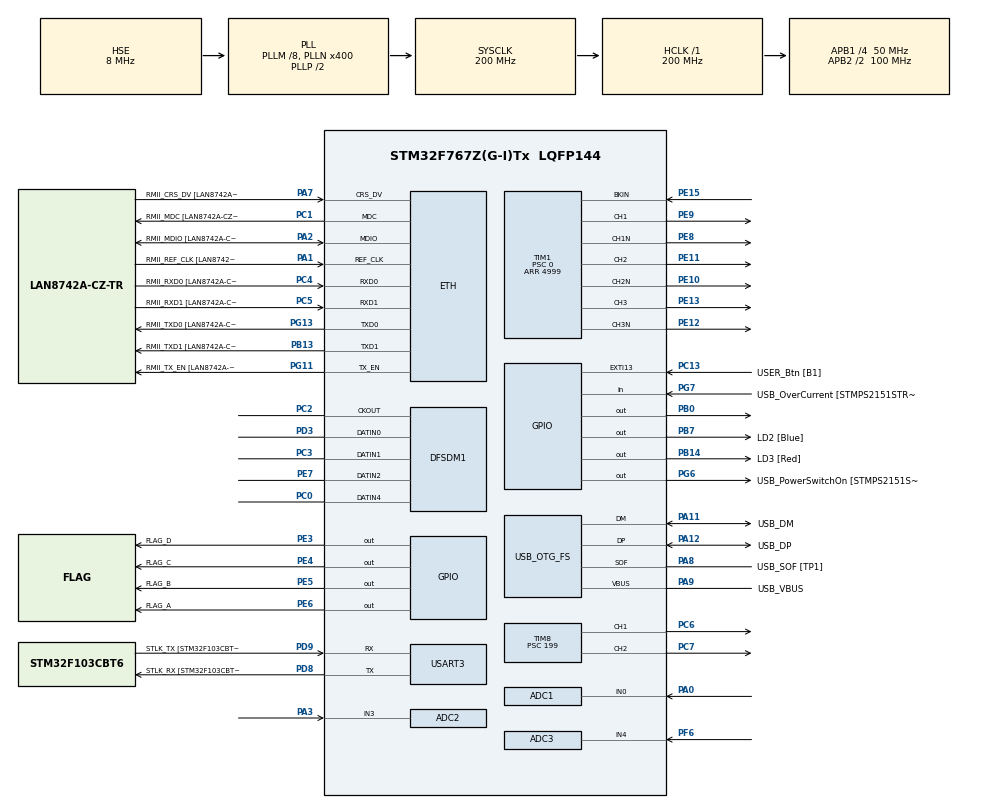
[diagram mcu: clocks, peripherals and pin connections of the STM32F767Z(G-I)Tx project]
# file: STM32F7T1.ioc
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ADC1.Channel-4\#ChannelRegularConversion=ADC_CHANNEL_0
ADC1.ClockPrescaler=ADC_CLOCK_SYNC_PCLK_DIV4
ADC1.NbrOfConversionFlag=1
ADC1.Rank-4\#ChannelRegularConversion=1
ADC1.SamplingTime-4\#ChannelRegularConversion=ADC_SAMPLETIME_3CYCLES
ADC1.master=1
ADC2.Channel-4\#ChannelRegularConversion=ADC_CHANNEL_3
ADC2.ClockPrescaler=ADC_CLOCK_SYNC_PCLK_DIV4
ADC2.NbrOfConversionFlag=1
ADC2.Rank-4\#ChannelRegularConversion=1
ADC2.SamplingTime-4\#ChannelRegularConversion=ADC_SAMPLETIME_3CYCLES
ADC3.Channel-0\#ChannelRegularConversion=ADC_CHANNEL_4
ADC3.ClockPrescaler=ADC_CLOCK_SYNC_PCLK_DIV4
ADC3.NbrOfConversionFlag=1
ADC3.Rank-0\#ChannelRegularConversion=1
ADC3.SamplingTime-0\#ChannelRegularConversion=ADC_SAMPLETIME_3CYCLES
CORTEX_M7.ART_ACCLERATOR_ENABLE=1
CORTEX_M7.CPU_DCache=Enabled
CORTEX_M7.CPU_ICache=Enabled
CORTEX_M7.PREFETCH_ENABLE=1
DFSDM1.Divider=256
DFSDM1.FastMode_reg_FIL0=ENABLE
DFSDM1.FastMode_reg_FIL1=ENABLE
DFSDM1.FastMode_reg_FIL2=ENABLE
DFSDM1.FastMode_reg_FIL3=ENABLE
DFSDM1.FilterOrder_CH0=DFSDM_CHANNEL_SINC3_ORDER
DFSDM1.FilterOrder_CH1=DFSDM_CHANNEL_SINC3_ORDER
DFSDM1.FilterOrder_CH2=DFSDM_CHANNEL_SINC3_ORDER
DFSDM1.FilterOrder_CH4=DFSDM_CHANNEL_SINC3_ORDER
DFSDM1.Filter_regChannel_FIL0=DFSDM_CHANNEL_0
DFSDM1.Filter_regChannel_FIL1=DFSDM_CHANNEL_1
DFSDM1.Filter_regChannel_FIL2=DFSDM_CHANNEL_2
DFSDM1.Filter_regChannel_FIL3=DFSDM_CHANNEL_4
DFSDM1.Fosr_FIL0=32
DFSDM1.Fosr_FIL1=32
DFSDM1.Fosr_FIL2=32
DFSDM1.Fosr_FIL3=32
DFSDM1.Oversampling_CH0=32
DFSDM1.Oversampling_CH1=32
DFSDM1.Oversampling_CH2=32
DFSDM1.Oversampling_CH4=32
DFSDM1.SincOrder_FIL0=DFSDM_FILTER_SINC3_ORDER
DFSDM1.SincOrder_FIL1=DFSDM_FILTER_SINC3_ORDER
DFSDM1.SincOrder_FIL2=DFSDM_FILTER_SINC3_ORDER
DFSDM1.SincOrder_FIL3=DFSDM_FILTER_SINC3_ORDER
ETH.MediaInterface=ETH_MEDIA_INTERFACE_RMII
FREERTOS.Tasks01=defaultTask,-3,128,StartDefaultTask,Default,NULL,Dynamic,NULL,NULL;TNBlinky,0,128,ThreadBlinky,As external,NULL,Dynamic,NULL,NULL;TNDFSDM,0,128,ThreadDFSDM,As external,NULL,Dynamic,NULL,NULL;TNCDC,0,128,ThreadCDC,As external,NULL,Dynamic,NULL,NULL;TNPWM,0,128,ThreadPWM,As external,NULL,Dynamic,NULL,NULL
FREERTOS.configLIBRARY_MAX_SYSCALL_INTERRUPT_PRIORITY=6
Mcu.Family=STM32F7
Mcu.Name=STM32F767Z(G-I)Tx
Mcu.Package=LQFP144
NVIC.OTG_FS_IRQn=true\:6\:0\:false\:false\:true\:true
NVIC.PriorityGroup=NVIC_PRIORITYGROUP_4
NVIC.TIM1_CC_IRQn=true\:6\:0\:false\:false\:true\:true
NVIC.TIM1_UP_TIM10_IRQn=true\:6\:0\:false\:false\:true\:true
NVIC.TIM3_IRQn=true\:6\:0\:false\:false\:true\:true
NVIC.TIM6_DAC_IRQn=true\:0\:0\:false\:false\:true\:false
NVIC.TimeBase=TIM6_DAC_IRQn
NVIC.TimeBaseIP=TIM6
PA0/WKUP.Signal=ADCx_IN0
PA1.GPIO_Label=RMII_REF_CLK [LAN8742A-CZ-TR_REFCLK0]
PA1.Mode=RMII
PA1.Signal=ETH_REF_CLK
PA10.Signal=USB_OTG_FS_ID
PA11.GPIO_Label=USB_DM
PA11.Mode=Device_Only
PA11.Signal=USB_OTG_FS_DM
PA12.GPIO_Label=USB_DP
PA12.Mode=Device_Only
PA12.Signal=USB_OTG_FS_DP
PA13.GPIO_Label=TMS
PA13.Mode=Trace_Asynchronous_SW
PA13.Signal=SYS_JTMS-SWDIO
PA14.GPIO_Label=TCK
PA14.Mode=Trace_Asynchronous_SW
PA14.Signal=SYS_JTCK-SWCLK
PA2.GPIO_Label=RMII_MDIO [LAN8742A-CZ-TR_MDIO]
PA2.Mode=RMII
PA2.Signal=ETH_MDIO
PA3.Signal=ADCx_IN3
PA7.GPIO_Label=RMII_CRS_DV [LAN8742A-CZ-TR_CRS_DV]
PA7.Mode=RMII
PA7.Signal=ETH_CRS_DV
PA8.GPIO_Label=USB_SOF [TP1]
PA8.Mode=Activate_SOF_FS
PA8.Signal=USB_OTG_FS_SOF
PA9.GPIO_Label=USB_VBUS
PA9.Mode=Activate_VBUS
PA9.Signal=USB_OTG_FS_VBUS
PB0.Signal=GPIO_Output
PB13.GPIO_Label=RMII_TXD1 [LAN8742A-CZ-TR_TXD1]
PB13.Mode=RMII
PB13.Signal=ETH_TXD1
PB14.GPIO_Label=LD3 [Red]
PB14.Signal=GPIO_Output
PB3.GPIO_Label=SW0
PB3.Mode=Trace_Asynchronous_SW
PB3.Signal=SYS_JTDO-SWO
PB7.GPIO_Label=LD2 [Blue]
PB7.Signal=GPIO_Output
PC0.Signal=S_DATAIN4DFSDM1
PC1.GPIO_Label=RMII_MDC [LAN8742A-CZ-TR_MDC]
PC1.Mode=RMII
PC1.Signal=ETH_MDC
PC13.GPIO_Label=USER_Btn [B1]
PC13.Signal=GPXTI13
PC14/OSC32_IN.Mode=LSE-External-Oscillator
PC14/OSC32_IN.Signal=RCC_OSC32_IN
PC15/OSC32_OUT.Mode=LSE-External-Oscillator
PC15/OSC32_OUT.Signal=RCC_OSC32_OUT
PC2.Signal=S_CKOUTDFSDM1
PC3.Signal=S_DATAIN1DFSDM1
PC4.GPIO_Label=RMII_RXD0 [LAN8742A-CZ-TR_RXD0]
PC4.Mode=RMII
PC4.Signal=ETH_RXD0
PC5.GPIO_Label=RMII_RXD1 [LAN8742A-CZ-TR_RXD1]
PC5.Mode=RMII
PC5.Signal=ETH_RXD1
PC6.Signal=S_TIM8_CH1
PC7.Signal=S_TIM8_CH2
PD3.Signal=S_DATAIN0DFSDM1
PD8.GPIO_Label=STLK_RX [STM32F103CBT6_PA3]
PD8.Mode=Asynchronous
PD8.Signal=USART3_TX
PD9.GPIO_Label=STLK_TX [STM32F103CBT6_PA2]
PD9.Mode=Asynchronous
PD9.Signal=USART3_RX
PE10.Mode=PWM Generation2 CH2 CH2N
PE10.Signal=TIM1_CH2N
PE11.Signal=S_TIM1_CH2
PE12.Mode=PWM Generation3 CH3 CH3N
PE12.Signal=TIM1_CH3N
PE13.Signal=S_TIM1_CH3
PE15.Mode=Activate-Break-Input
PE15.Signal=TIM1_BKIN
PE3.GPIO_Label=FLAG_D
PE3.GPIO_ModeDefaultOutputPP=GPIO_MODE_OUTPUT_OD
PE3.GPIO_PuPd=GPIO_PULLUP
PE3.GPIO_Speed=GPIO_SPEED_FREQ_MEDIUM
PE3.Signal=GPIO_Output
PE4.GPIO_Label=FLAG_C
PE4.GPIO_ModeDefaultOutputPP=GPIO_MODE_OUTPUT_OD
PE4.GPIO_PuPd=GPIO_PULLUP
PE4.GPIO_Speed=GPIO_SPEED_FREQ_MEDIUM
PE4.Signal=GPIO_Output
PE5.GPIO_Label=FLAG_B
PE5.GPIO_ModeDefaultOutputPP=GPIO_MODE_OUTPUT_OD
PE5.GPIO_PuPd=GPIO_PULLUP
PE5.GPIO_Speed=GPIO_SPEED_FREQ_MEDIUM
PE5.PinState=GPIO_PIN_RESET
PE5.Signal=GPIO_Output
PE6.GPIO_Label=FLAG_A
PE6.GPIO_ModeDefaultOutputPP=GPIO_MODE_OUTPUT_OD
PE6.GPIO_PuPd=GPIO_PULLUP
PE6.GPIO_Speed=GPIO_SPEED_FREQ_MEDIUM
PE6.Signal=GPIO_Output
PE7.Signal=S_DATAIN2DFSDM1
PE8.Mode=PWM Generation1 CH1 CH1N
PE8.Signal=TIM1_CH1N
PE9.Signal=S_TIM1_CH1
PF6.Mode=IN4
PF6.Signal=ADC3_IN4
PG11.GPIO_Label=RMII_TX_EN [LAN8742A-CZ-TR_TXEN]
PG11.Mode=RMII
PG11.Signal=ETH_TX_EN
PG13.GPIO_Label=RMII_TXD0 [LAN8742A-CZ-TR_TXD0]
PG13.Mode=RMII
PG13.Signal=ETH_TXD0
PG6.GPIO_Label=USB_PowerSwitchOn [STMPS2151STR_EN]
PG6.Signal=GPIO_Output
PG7.GPIO_Label=USB_OverCurrent [STMPS2151STR_FAULT]
PG7.Signal=GPIO_Input
PH0/OSC_IN.GPIO_Label=MCO [STM32F103CBT6_PA8]
PH0/OSC_IN.Mode=HSE-External-Clock-Source
PH0/OSC_IN.Signal=RCC_OSC_IN
PH1/OSC_OUT.Mode=HSE-External-Clock-Source
PH1/OSC_OUT.Signal=RCC_OSC_OUT
ProjectManager.HeapSize=0x200
ProjectManager.StackSize=0x400
ProjectManager.TargetToolchain=SW4STM32
RCC.48MHZClocksFreq_Value=24000000
RCC.AHBFreq_Value=200000000
RCC.APB1CLKDivider=RCC_HCLK_DIV4
RCC.APB1Freq_Value=50000000
RCC.APB1TimFreq_Value=100000000
RCC.APB2CLKDivider=RCC_HCLK_DIV2
RCC.APB2Freq_Value=100000000
RCC.APB2TimFreq_Value=200000000
RCC.CortexFreq_Value=200000000
RCC.DFSDMSelection=RCC_DFSDM1CLKSOURCE_SYSCLK
RCC.HCLKFreq_Value=200000000
RCC.HSE_VALUE=8000000
RCC.HSI_VALUE=16000000
RCC.PLL48CLockSelection=RCC_CLK48SOURCE_PLLSAIP
RCC.PLLM=8
RCC.PLLMUL=RCC_PLL_MUL9
RCC.PLLN=400
RCC.PLLSAIP=RCC_PLLSAIP_DIV4
RCC.PRESCALERUSB=RCC_USBCLKSOURCE_PLL_DIV1_5
RCC.SYSCLKFreq_VALUE=200000000
RCC.SYSCLKSource=RCC_SYSCLKSOURCE_PLLCLK
RCC.SYSCLKSourceVirtual=RCC_SYSCLKSOURCE_PLLCLK
RCC.USART3CLockSelection=RCC_USART3CLKSOURCE_SYSCLK
RCC.USBFreq_Value=48000000
RCC.VCOOutputFreq_Value=400000000
SH.ADCx_IN0.0=ADC1_IN0,IN0
SH.ADCx_IN3.0=ADC2_IN3,IN3
SH.S_CKOUTDFSDM1.0=DFSDM1_CKOUT,PDM_SPI_input_from_ch0_and_internal_clock
SH.S_CKOUTDFSDM1.1=DFSDM1_CKOUT,PDM_SPI_input_from_ch1_and_internal_clock
SH.S_CKOUTDFSDM1.2=DFSDM1_CKOUT,PDM_SPI_input_from_ch2_and_internal_clock
SH.S_CKOUTDFSDM1.3=DFSDM1_CKOUT,CKOUT
SH.S_CKOUTDFSDM1.4=DFSDM1_CKOUT,PDM_SPI_input_from_ch4_and_internal_clock
SH.S_DATAIN0DFSDM1.0=DFSDM1_DATIN0,PDM_SPI_input_from_ch0_and_internal_clock
SH.S_DATAIN1DFSDM1.0=DFSDM1_DATIN1,PDM_SPI_input_from_ch1_and_internal_clock
SH.S_DATAIN2DFSDM1.0=DFSDM1_DATIN2,PDM_SPI_input_from_ch2_and_internal_clock
SH.S_DATAIN4DFSDM1.0=DFSDM1_DATIN4,PDM_SPI_input_from_ch4_and_internal_clock
SH.S_TIM1_CH1.0=TIM1_CH1,PWM Generation1 CH1 CH1N
SH.S_TIM1_CH2.0=TIM1_CH2,PWM Generation2 CH2 CH2N
SH.S_TIM1_CH3.0=TIM1_CH3,PWM Generation3 CH3 CH3N
SH.S_TIM8_CH1.0=TIM8_CH1,Output Compare1 CH1
SH.S_TIM8_CH2.0=TIM8_CH2,Output Compare2 CH2
TIM1.AutomaticOutput=TIM_AUTOMATICOUTPUT_ENABLE
TIM1.BreakState=TIM_BREAK_DISABLE
TIM1.Channel-Output\ Compare4\ No\ Output=TIM_CHANNEL_4
TIM1.Channel-PWM\ Generation1\ CH1\ CH1N=TIM_CHANNEL_1
TIM1.Channel-PWM\ Generation2\ CH2\ CH2N=TIM_CHANNEL_2
TIM1.Channel-PWM\ Generation3\ CH3\ CH3N=TIM_CHANNEL_3
TIM1.ClockDivision=TIM_CLOCKDIVISION_DIV4
TIM1.CounterMode=TIM_COUNTERMODE_CENTERALIGNED1
TIM1.DeadTime=50
TIM1.OCMode_PWM-PWM\ Generation1\ CH1\ CH1N=TIM_OCMODE_PWM1
TIM1.OCMode_PWM-PWM\ Generation2\ CH2\ CH2N=TIM_OCMODE_PWM1
TIM1.OCMode_PWM-PWM\ Generation3\ CH3\ CH3N=TIM_OCMODE_PWM1
TIM1.Period=4999
TIM1.Prescaler=0
TIM1.Pulse-Output\ Compare4\ No\ Output=400
TIM1.Pulse-PWM\ Generation1\ CH1\ CH1N=30
TIM1.Pulse-PWM\ Generation2\ CH2\ CH2N=13
TIM1.Pulse-PWM\ Generation3\ CH3\ CH3N=18
TIM1.RepetitionCounter=0
TIM1.SourceBRKDigInput=TIM_BREAKINPUTSOURCE_DISABLE
TIM1.TIM_MasterOutputTrigger=TIM_TRGO_UPDATE
TIM1.TIM_MasterOutputTrigger2=TIM_TRGO2_OC6REF
TIM1.TIM_MasterSlaveMode=TIM_MASTERSLAVEMODE_ENABLE
TIM3.Period=3
TIM3.TIM_MasterOutputTrigger=TIM_TRGO_UPDATE
TIM3.TIM_MasterSlaveMode=TIM_MASTERSLAVEMODE_DISABLE
TIM7.Period=999
TIM7.Prescaler=19
TIM8.Channel-Output\ Compare1\ CH1=TIM_CHANNEL_1
TIM8.Channel-Output\ Compare2\ CH2=TIM_CHANNEL_2
TIM8.Period=1000
TIM8.Prescaler=199
USART3.VirtualMode-Asynchronous=VM_ASYNC
USB_DEVICE.CLASS_NAME_FS=CDC
USB_DEVICE.SERIALNUMBER_STRING_CDC_FS=22345112
USB_DEVICE.VirtualModeFS=Cdc_FS
USB_OTG_FS.VirtualMode=Device_Only
VP_FREERTOS_VS_ENABLE.Mode=Enabled
VP_SYS_VS_tim6.Mode=TIM6
VP_TIM1_VS_ClockSourceINT.Mode=Internal
VP_TIM1_VS_no_output4.Mode=Output Compare4 No Output
VP_TIM3_VS_ClockSourceITR.Mode=TriggerSource_ITR0
VP_TIM3_VS_ControllerModeClock.Mode=Clock Mode
VP_TIM7_VS_ClockSourceINT.Mode=Enable_Timer
VP_TIM8_VS_ClockSourceINT.Mode=Internal
VP_USB_DEVICE_VS_USB_DEVICE_CDC_FS.Mode=CDC_FS
board=NUCLEO-F767ZI

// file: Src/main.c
/**
  ******************************************************************************
  * File Name          : main.c
  * Description        : Main program body
  ******************************************************************************
  * This notice applies to any and all portions of this file
  * that are not between comment pairs USER CODE BEGIN and
  * USER CODE END. Other portions of this file, whether
  * inserted by the user or by software development tools
  * are owned by their respective copyright owners.
  *
  * Copyright (c) 2017 STMicroelectronics International N.V.
  * All rights reserved.
  *
  * Redistribution and use in source and binary forms, with or without
  * modification, are permitted, provided that the following conditions are met:
  *
  * 1. Redistribution of source code must retain the above copyright notice,
  *    this list of conditions and the following disclaimer.
  * 2. Redistributions in binary form must reproduce the above copyright notice,
  *    this list of conditions and the following disclaimer in the documentation
  *    and/or other materials provided with the distribution.
  * 3. Neither the name of STMicroelectronics nor the names of other
  *    contributors to this software may be used to endorse or promote products
  *    derived from this software without specific written permission.
  * 4. This software, including modifications and/or derivative works of this
  *    software, must execute solely and exclusively on microcontroller or
  *    microprocessor devices manufactured by or for STMicroelectronics.
  * 5. Redistribution and use of this software other than as permitted under
  *    this license is void and will automatically terminate your rights under
  *    this license.
  *
  * THIS SOFTWARE IS PROVIDED BY STMICROELECTRONICS AND CONTRIBUTORS "AS IS"
  * AND ANY EXPRESS, IMPLIED OR STATUTORY WARRANTIES, INCLUDING, BUT NOT
  * LIMITED TO, THE IMPLIED WARRANTIES OF MERCHANTABILITY, FITNESS FOR A
  * PARTICULAR PURPOSE AND NON-INFRINGEMENT OF THIRD PARTY INTELLECTUAL PROPERTY
  * RIGHTS ARE DISCLAIMED TO THE FULLEST EXTENT PERMITTED BY LAW. IN NO EVENT
  * SHALL STMICROELECTRONICS OR CONTRIBUTORS BE LIABLE FOR ANY DIRECT, INDIRECT,
  * INCIDENTAL, SPECIAL, EXEMPLARY, OR CONSEQUENTIAL DAMAGES (INCLUDING, BUT NOT
  * LIMITED TO, PROCUREMENT OF SUBSTITUTE GOODS OR SERVICES; LOSS OF USE, DATA,
  * OR PROFITS; OR BUSINESS INTERRUPTION) HOWEVER CAUSED AND ON ANY THEORY OF
  * LIABILITY, WHETHER IN CONTRACT, STRICT LIABILITY, OR TORT (INCLUDING
  * NEGLIGENCE OR OTHERWISE) ARISING IN ANY WAY OUT OF THE USE OF THIS SOFTWARE,
  * EVEN IF ADVISED OF THE POSSIBILITY OF SUCH DAMAGE.
  *
  ******************************************************************************
  */
#include "main.h"
#include "stm32f7xx_hal.h"
#include "cmsis_os.h"
#include "adc.h"
#include "dfsdm.h"
#include "eth.h"
#include "tim.h"
#include "usart.h"
#include "usb_device.h"
#include "gpio.h"

/* USER CODE BEGIN Includes */
#include "intersect/event.h"
/* USER CODE END Includes */

/* USER CODE BEGIN PV */
/* Private variables ---------------------------------------------------------*/

/* USER CODE END PV */

void SystemClock_Config(void);
void MX_FREERTOS_Init(void);

/* USER CODE BEGIN PFP */
/* Private function prototypes -----------------------------------------------*/

/* USER CODE END PFP */

extern uint32_t g_pfnVectors;
extern uint32_t _vector_table_start;
//extern uint32_t isr_vector;

uint32_t readback;

int main(void)
{

  /* USER CODE BEGIN 1 */
	//SCB->VTOR = isr_vector;
	SCB->VTOR = _vector_table_start;
	SCB->VTOR = 0X08010000;
	readback = SCB->VTOR;
	/* USER CODE END 1 */

  /* Enable I-Cache-------------------------------------------------------------*/
  SCB_EnableICache();

  /* Enable D-Cache-------------------------------------------------------------*/
  SCB_EnableDCache();

  /* MCU Configuration----------------------------------------------------------*/

  /* Reset of all peripherals, Initializes the Flash interface and the Systick. */
  HAL_Init();

  /* Configure the system clock */
  SystemClock_Config();

  /* Initialize all configured peripherals */
  MX_GPIO_Init();
  MX_DFSDM1_Init();
  MX_TIM1_Init();
  MX_ADC1_Init();
  MX_ADC2_Init();
  MX_ADC3_Init();
  MX_TIM3_Init();
  MX_ETH_Init();
  MX_USART3_UART_Init();
  MX_TIM8_Init();
  MX_TIM7_Init();

  /* Call init function for freertos objects (in freertos.c) */
  MX_FREERTOS_Init();

  /* Start scheduler */
  osKernelStart();

  /* We should never get here as control is now taken by the scheduler */

  /* Infinite loop */
  while (1)
  {

  }

}

/** System Clock Configuration
*/
void SystemClock_Config(void)
{

  RCC_OscInitTypeDef RCC_OscInitStruct;
  RCC_ClkInitTypeDef RCC_ClkInitStruct;
  RCC_PeriphCLKInitTypeDef PeriphClkInitStruct;

    /**Configure the main internal regulator output voltage
    */
  __HAL_RCC_PWR_CLK_ENABLE();

  __HAL_PWR_VOLTAGESCALING_CONFIG(PWR_REGULATOR_VOLTAGE_SCALE1);

    /**Initializes the CPU, AHB and APB busses clocks
    */
  RCC_OscInitStruct.OscillatorType = RCC_OSCILLATORTYPE_HSE;
  RCC_OscInitStruct.HSEState = RCC_HSE_BYPASS;
  RCC_OscInitStruct.PLL.PLLState = RCC_PLL_ON;
  RCC_OscInitStruct.PLL.PLLSource = RCC_PLLSOURCE_HSE;
  RCC_OscInitStruct.PLL.PLLM = 8;
  RCC_OscInitStruct.PLL.PLLN = 400;
  RCC_OscInitStruct.PLL.PLLP = RCC_PLLP_DIV2;
  RCC_OscInitStruct.PLL.PLLQ = 2;
  if (HAL_RCC_OscConfig(&RCC_OscInitStruct) != HAL_OK)
  {
    _Error_Handler(__FILE__, __LINE__);
  }

    /**Activate the Over-Drive mode
    */
  if (HAL_PWREx_EnableOverDrive() != HAL_OK)
  {
    _Error_Handler(__FILE__, __LINE__);
  }

    /**Initializes the CPU, AHB and APB busses clocks
    */
  RCC_ClkInitStruct.ClockType = RCC_CLOCKTYPE_HCLK|RCC_CLOCKTYPE_SYSCLK
                              |RCC_CLOCKTYPE_PCLK1|RCC_CLOCKTYPE_PCLK2;
  RCC_ClkInitStruct.SYSCLKSource = RCC_SYSCLKSOURCE_PLLCLK;
  RCC_ClkInitStruct.AHBCLKDivider = RCC_SYSCLK_DIV1;
  RCC_ClkInitStruct.APB1CLKDivider = RCC_HCLK_DIV4;
  RCC_ClkInitStruct.APB2CLKDivider = RCC_HCLK_DIV2;

  if (HAL_RCC_ClockConfig(&RCC_ClkInitStruct, FLASH_LATENCY_6) != HAL_OK)
  {
    _Error_Handler(__FILE__, __LINE__);
  }

  PeriphClkInitStruct.PeriphClockSelection = RCC_PERIPHCLK_DFSDM1|RCC_PERIPHCLK_USART3
                              |RCC_PERIPHCLK_CLK48;
  PeriphClkInitStruct.PLLSAI.PLLSAIN = 192;
  PeriphClkInitStruct.PLLSAI.PLLSAIR = 2;
  PeriphClkInitStruct.PLLSAI.PLLSAIQ = 2;
  PeriphClkInitStruct.PLLSAI.PLLSAIP = RCC_PLLSAIP_DIV4;
  PeriphClkInitStruct.PLLSAIDivQ = 1;
  PeriphClkInitStruct.PLLSAIDivR = RCC_PLLSAIDIVR_2;
  PeriphClkInitStruct.Usart3ClockSelection = RCC_USART3CLKSOURCE_SYSCLK;
  PeriphClkInitStruct.Clk48ClockSelection = RCC_CLK48SOURCE_PLLSAIP;
  PeriphClkInitStruct.Dfsdm1ClockSelection = RCC_DFSDM1CLKSOURCE_SYSCLK;
  if (HAL_RCCEx_PeriphCLKConfig(&PeriphClkInitStruct) != HAL_OK)
  {
    _Error_Handler(__FILE__, __LINE__);
  }

    /**Configure the Systick interrupt time
    */
  HAL_SYSTICK_Config(HAL_RCC_GetHCLKFreq()/1000);

    /**Configure the Systick
    */
  HAL_SYSTICK_CLKSourceConfig(SYSTICK_CLKSOURCE_HCLK);

  /* SysTick_IRQn interrupt configuration */
  HAL_NVIC_SetPriority(SysTick_IRQn, 15, 0);
}

void HAL_TIM_PeriodElapsedCallback(TIM_HandleTypeDef *htim)
{
/* USER CODE BEGIN Callback 0 */
	  if (htim->Instance == TIM1)
	  {
	    interrupt_tim1_update(htim);
	  }
	  if (htim->Instance == TIM3)
	  {
	    interrupt_tim3_update(htim);
	  }
/* USER CODE END Callback 0 */
  if (htim->Instance == TIM6) {
    HAL_IncTick();
  }
}

void _Error_Handler(char * file, int line)
{
  while(1)
  {
  }
}

/************************ (C) COPYRIGHT STMicroelectronics *****END OF FILE****/

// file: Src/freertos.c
/**
  ******************************************************************************
  * File Name          : freertos.c
  * Description        : Code for freertos applications
  ******************************************************************************
  * This notice applies to any and all portions of this file
  * that are not between comment pairs USER CODE BEGIN and
  * USER CODE END. Other portions of this file, whether
  * inserted by the user or by software development tools
  * are owned by their respective copyright owners.
  *
  * Copyright (c) 2017 STMicroelectronics International N.V.
  * All rights reserved.
  *
  * Redistribution and use in source and binary forms, with or without
  * modification, are permitted, provided that the following conditions are met:
  *
  * 1. Redistribution of source code must retain the above copyright notice,
  *    this list of conditions and the following disclaimer.
  * 2. Redistributions in binary form must reproduce the above copyright notice,
  *    this list of conditions and the following disclaimer in the documentation
  *    and/or other materials provided with the distribution.
  * 3. Neither the name of STMicroelectronics nor the names of other
  *    contributors to this software may be used to endorse or promote products
  *    derived from this software without specific written permission.
  * 4. This software, including modifications and/or derivative works of this
  *    software, must execute solely and exclusively on microcontroller or
  *    microprocessor devices manufactured by or for STMicroelectronics.
  * 5. Redistribution and use of this software other than as permitted under
  *    this license is void and will automatically terminate your rights under
  *    this license.
  *
  * THIS SOFTWARE IS PROVIDED BY STMICROELECTRONICS AND CONTRIBUTORS "AS IS"
  * AND ANY EXPRESS, IMPLIED OR STATUTORY WARRANTIES, INCLUDING, BUT NOT
  * LIMITED TO, THE IMPLIED WARRANTIES OF MERCHANTABILITY, FITNESS FOR A
  * PARTICULAR PURPOSE AND NON-INFRINGEMENT OF THIRD PARTY INTELLECTUAL PROPERTY
  * RIGHTS ARE DISCLAIMED TO THE FULLEST EXTENT PERMITTED BY LAW. IN NO EVENT
  * SHALL STMICROELECTRONICS OR CONTRIBUTORS BE LIABLE FOR ANY DIRECT, INDIRECT,
  * INCIDENTAL, SPECIAL, EXEMPLARY, OR CONSEQUENTIAL DAMAGES (INCLUDING, BUT NOT
  * LIMITED TO, PROCUREMENT OF SUBSTITUTE GOODS OR SERVICES; LOSS OF USE, DATA,
  * OR PROFITS; OR BUSINESS INTERRUPTION) HOWEVER CAUSED AND ON ANY THEORY OF
  * LIABILITY, WHETHER IN CONTRACT, STRICT LIABILITY, OR TORT (INCLUDING
  * NEGLIGENCE OR OTHERWISE) ARISING IN ANY WAY OUT OF THE USE OF THIS SOFTWARE,
  * EVEN IF ADVISED OF THE POSSIBILITY OF SUCH DAMAGE.
  *
  ******************************************************************************
  */

#include "FreeRTOS.h"
#include "task.h"
#include "cmsis_os.h"

/* USER CODE BEGIN Includes */
#include "intersect/DefaultTask.h"
/* USER CODE END Includes */

osThreadId defaultTaskHandle;
osThreadId TNBlinkyHandle;
osThreadId TNDFSDMHandle;
osThreadId TNCDCHandle;

void StartDefaultTask(void const * argument);
extern void ThreadBlinky(void const * argument);
extern void ThreadDFSDM(void const * argument);
extern void ThreadCDC(void const * argument);

extern void MX_USB_DEVICE_Init(void);
void MX_FREERTOS_Init(void); /* (MISRA C 2004 rule 8.1) */

/* Hook prototypes */

/* Init FreeRTOS */

void MX_FREERTOS_Init(void) {

  /* Create the thread(s) */
  /* definition and creation of defaultTask */
  osThreadDef(defaultTask, StartDefaultTask, osPriorityNormal, 0, 128);
  defaultTaskHandle = osThreadCreate(osThread(defaultTask), NULL);

  /* definition and creation of TNBlinky */
  osThreadDef(TNBlinky, ThreadBlinky, osPriorityIdle, 0, 128);
  TNBlinkyHandle = osThreadCreate(osThread(TNBlinky), NULL);

  /* definition and creation of TNDFSDM */
  osThreadDef(TNDFSDM, ThreadDFSDM, osPriorityIdle, 0, 128);
  TNDFSDMHandle = osThreadCreate(osThread(TNDFSDM), NULL);

  /* definition and creation of TNCDC */
  osThreadDef(TNCDC, ThreadCDC, osPriorityIdle, 0, 128);
  TNCDCHandle = osThreadCreate(osThread(TNCDC), NULL);

}

/* StartDefaultTask function */
void StartDefaultTask(void const * argument)
{
  /* init code for USB_DEVICE */
  MX_USB_DEVICE_Init();

  /* USER CODE BEGIN StartDefaultTask */
  DefaultTaskEntry();
  /* Infinite loop */
  for(;;)
  {
    osDelay(1);
  }
  /* USER CODE END StartDefaultTask */
}

/************************ (C) COPYRIGHT STMicroelectronics *****END OF FILE****/
